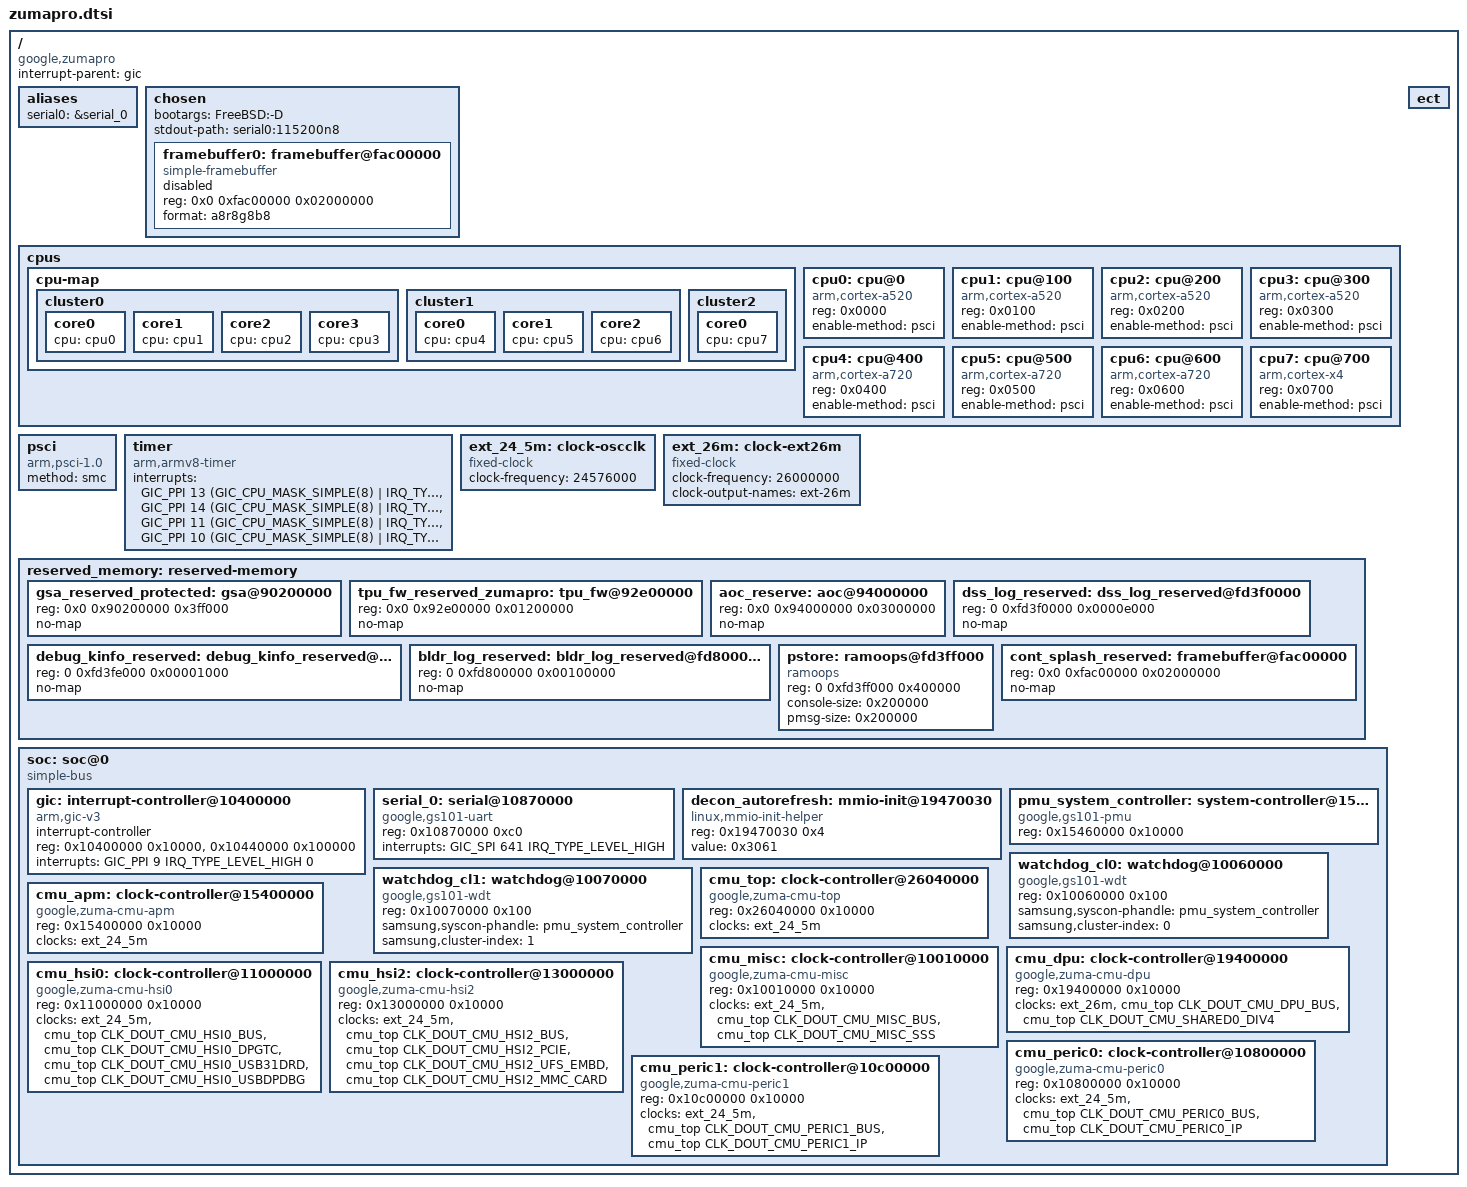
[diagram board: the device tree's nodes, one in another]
// SPDX-License-Identifier: (GPL-2.0-only OR BSD-2-Clause)
/*
 * Google Tensor G4 "zumapro" SoC.
 *
 * Minimal FreeBSD support: CPUs, PSCI, the GICv3 interrupt controller and
 * the ARM architected timer.  These are all handled by FreeBSD's generic
 * arm64 drivers.  SoC-specific clock (CMU), pinctrl and USI support is not
 * present yet; peripherals depend on the configuration left in place by the
 * bootloader.
 *
 * Copyright 2025 Trijal Saha <trijalsaha2012@gmail.com>
 */

#include <dt-bindings/clock/google,zuma.h>
#include <dt-bindings/interrupt-controller/arm-gic.h>

/ {
	compatible = "google,zumapro", "google,gs101";
	interrupt-parent = <&gic>;
	#address-cells = <2>;
	#size-cells = <1>;

	aliases {
		serial0 = &serial_0;
	};

	chosen {
		/*
		 * The stock bootloader crashes if /chosen has no "bootargs".
		 * FreeBSD only parses bootargs beginning with the "FreeBSD:"
		 * guard -- this is exactly how it ignores Linux-style args --
		 * and treats the remainder as boot flags.  "-D" sets
		 * RB_MULTIPLE so every probed console stays active; otherwise
		 * the vt_simplefb framebuffer (CN_INTERNAL) outranks and
		 * silences the serial console once cninit() picks one best
		 * console.
		 */
		bootargs = "FreeBSD:-D";
		stdout-path = "serial0:115200n8";
		
		/*
		 * Framebuffer set up by the bootloader.  FreeBSD's vt_simplefb
		 * driver takes the base address from "reg" (it does not follow
		 * the Linux "memory-region" phandle), so the splash buffer is
		 * described directly here and reserved below.  The per-board
		 * geometry (width, height, stride) is filled in and the node is
		 * enabled by each board's device tree.
		 */
		framebuffer0: framebuffer@fac00000 {
			compatible = "simple-framebuffer";
			reg = <0x0 0xfac00000 0x02000000>;
			format = "a8r8g8b8";
			status = "disabled";
		};
	};

	cpus {
		#address-cells = <1>;
		#size-cells = <0>;

		cpu-map {
			cluster0 {
				core0 { cpu = <&cpu0>; };
				core1 { cpu = <&cpu1>; };
				core2 { cpu = <&cpu2>; };
				core3 { cpu = <&cpu3>; };
			};

			cluster1 {
				core0 { cpu = <&cpu4>; };
				core1 { cpu = <&cpu5>; };
				core2 { cpu = <&cpu6>; };
			};

			cluster2 {
				core0 { cpu = <&cpu7>; };
			};
		};

		cpu0: cpu@0 {
			device_type = "cpu";
			compatible = "arm,cortex-a520";
			reg = <0x0000>;
			enable-method = "psci";
		};

		cpu1: cpu@100 {
			device_type = "cpu";
			compatible = "arm,cortex-a520";
			reg = <0x0100>;
			enable-method = "psci";
		};

		cpu2: cpu@200 {
			device_type = "cpu";
			compatible = "arm,cortex-a520";
			reg = <0x0200>;
			enable-method = "psci";
		};

		cpu3: cpu@300 {
			device_type = "cpu";
			compatible = "arm,cortex-a520";
			reg = <0x0300>;
			enable-method = "psci";
		};

		cpu4: cpu@400 {
			device_type = "cpu";
			compatible = "arm,cortex-a720";
			reg = <0x0400>;
			enable-method = "psci";
		};

		cpu5: cpu@500 {
			device_type = "cpu";
			compatible = "arm,cortex-a720";
			reg = <0x0500>;
			enable-method = "psci";
		};

		cpu6: cpu@600 {
			device_type = "cpu";
			compatible = "arm,cortex-a720";
			reg = <0x0600>;
			enable-method = "psci";
		};

		cpu7: cpu@700 {
			device_type = "cpu";
			compatible = "arm,cortex-x4";
			reg = <0x0700>;
			enable-method = "psci";
		};
	};

	psci {
		compatible = "arm,psci-1.0";
		method = "smc";
	};

	timer {
		compatible = "arm,armv8-timer";
		interrupts =
		    <GIC_PPI 13 (GIC_CPU_MASK_SIMPLE(8) | IRQ_TYPE_LEVEL_LOW) 0>,
		    <GIC_PPI 14 (GIC_CPU_MASK_SIMPLE(8) | IRQ_TYPE_LEVEL_LOW) 0>,
		    <GIC_PPI 11 (GIC_CPU_MASK_SIMPLE(8) | IRQ_TYPE_LEVEL_LOW) 0>,
		    <GIC_PPI 10 (GIC_CPU_MASK_SIMPLE(8) | IRQ_TYPE_LEVEL_LOW) 0>;
	};

	/*
	 * Reference oscillators.  The CMU clock controllers below take "oscclk"
	 * from ext_24_5m; its rate is the root of the whole clock tree.
	 */
	/*
	 * No clock-output-names: the FreeBSD fixed-clock driver would register
	 * it under that global name and collide with the "oscclk" node the
	 * exynos_clk driver registers internally.  The CMUs still reach this
	 * oscillator through their "oscclk" clock-names input (by phandle), so
	 * the rate is read from here while the global "oscclk" stays unique.
	 */
	ext_24_5m: clock-oscclk {
		compatible = "fixed-clock";
		#clock-cells = <0>;
		clock-frequency = <24576000>;
	};

	ext_26m: clock-ext26m {
		compatible = "fixed-clock";
		#clock-cells = <0>;
		clock-frequency = <26000000>;
		clock-output-names = "ext-26m";
	};

	/*
	 * Firmware and TrustZone carve-outs.  These must not be used by the
	 * kernel; they are reserved by the secure firmware and the bootloader.
	 */
	/* Energy/clock tables populated by the bootloader; must be present. */
	ect {
	};

	/*
	 * The stock bootloader inspects and populates these reserved regions
	 * before handing off, so the names, labels and addresses must match
	 * what it expects (i.e. the upstream Linux device tree) exactly.
	 */
	reserved_memory: reserved-memory {
		#address-cells = <2>;
		#size-cells = <1>;
		ranges;

		gsa_reserved_protected: gsa@90200000 {
			reg = <0x0 0x90200000 0x3ff000>;
			no-map;
		};

		tpu_fw_reserved_zumapro: tpu_fw@92e00000 {
			reg = <0x0 0x92e00000 0x01200000>;
			no-map;
		};

		aoc_reserve: aoc@94000000 {
			reg = <0x0 0x94000000 0x03000000>;
			no-map;
		};

		dss_log_reserved: dss_log_reserved@fd3f0000 {
			reg = <0 0xfd3f0000 0x0000e000>;
			no-map;
		};

		debug_kinfo_reserved: debug_kinfo_reserved@fd3fe000 {
			reg = <0 0xfd3fe000 0x00001000>;
			no-map;
		};

		bldr_log_reserved: bldr_log_reserved@fd800000 {
			reg = <0 0xfd800000 0x00100000>;
			no-map;
		};

		pstore: ramoops@fd3ff000 {
			compatible = "ramoops";
			reg = <0 0xfd3ff000 0x400000>;
			console-size = <0x200000>;
			pmsg-size = <0x200000>;
		};

		/*
		 * Bootloader splash / continuous-splash framebuffer.  Reserved
		 * so the kernel does not reuse it as RAM; consumed by the
		 * simple-framebuffer node under /chosen.  Sized to cover the
		 * largest panel of any board in this family.
		 */
		cont_splash_reserved: framebuffer@fac00000 {
			reg = <0x0 0xfac00000 0x02000000>;
			no-map;
		};
	};

	soc: soc@0 {
		compatible = "simple-bus";
		#address-cells = <1>;
		#size-cells = <1>;
		ranges = <0x0 0x0 0x0 0x40000000>;

		gic: interrupt-controller@10400000 {
			compatible = "arm,gic-v3";
			/*
			 * Four-cell binding to match the upstream Linux DTS.
			 * FreeBSD's gic_v3 driver uses the first three cells
			 * (type, number, flags) and ignores the fourth (the PPI
			 * partition index), which it does not implement.
			 */
			#interrupt-cells = <4>;
			interrupt-controller;
			reg = <0x10400000 0x10000>,	/* GICD */
			      <0x10440000 0x100000>;	/* GICR * 8 */
			interrupts = <GIC_PPI 9 IRQ_TYPE_LEVEL_HIGH 0>;
		};

		/*
		 * Debug UART (USI8 in UART mode).  The exynos4210-compatible
		 * UART is wrapped in a USI block; the USI mode and the gating
		 * clocks are left configured by the bootloader, so the UART is
		 * described directly here rather than under a USI node.
		 */
		serial_0: serial@10870000 {
			compatible = "google,gs101-uart";
			reg = <0x10870000 0xc0>;
			interrupts = <GIC_SPI 641 IRQ_TYPE_LEVEL_HIGH>;
		};

		/*
		 * Set the DECON display-controller autorefresh bit so the
		 * framebuffer the bootloader set up keeps scanning out.  This
		 * is a one-shot register write handled by the mmio_init driver.
		 */
		decon_autorefresh: mmio-init@19470030 {
			compatible = "linux,mmio-init-helper";
			reg = <0x19470030 0x4>;
			value = <0x3061>;
		};

		/*
		 * Power Management Unit register block, exposed as a syscon so
		 * the watchdog (and later reboot/poweroff) can reach the PMU
		 * reset controls.  FreeBSD's generic syscon driver binds on the
		 * "syscon" compatible; no PMU-specific driver, clock or USI is
		 * needed.
		 */
		pmu_system_controller: system-controller@15460000 {
			compatible = "google,gs101-pmu", "syscon";
			reg = <0x15460000 0x10000>;
		};

		/*
		 * CPU cluster watchdogs.  Placed after the PMU node so the
		 * syscon they reference attaches first (all bind in the same
		 * bus pass, in device-tree order).
		 */
		watchdog_cl0: watchdog@10060000 {
			compatible = "google,gs101-wdt";
			reg = <0x10060000 0x100>;
			samsung,syscon-phandle = <&pmu_system_controller>;
			samsung,cluster-index = <0>;
		};

		watchdog_cl1: watchdog@10070000 {
			compatible = "google,gs101-wdt";
			reg = <0x10070000 0x100>;
			samsung,syscon-phandle = <&pmu_system_controller>;
			samsung,cluster-index = <1>;
		};

		/*
		 * Clock Management Units.  CMU_TOP is the root of the clock
		 * tree; the other domains take their bus clocks from it.  The
		 * FreeBSD exynos_clk driver brings CMU_TOP up at an earlier bus
		 * pass so its outputs are registered before the leaf domains
		 * resolve them by name.  The samsung,sysreg phandles used by
		 * Linux for dynamic root-clock gating are omitted; that path is
		 * not implemented and the clocks are left as firmware set them.
		 */
		cmu_top: clock-controller@26040000 {
			compatible = "google,zuma-cmu-top";
			reg = <0x26040000 0x10000>;
			#clock-cells = <1>;
			clocks = <&ext_24_5m>;
			clock-names = "oscclk";
		};

		cmu_apm: clock-controller@15400000 {
			compatible = "google,zuma-cmu-apm";
			reg = <0x15400000 0x10000>;
			#clock-cells = <1>;
			clocks = <&ext_24_5m>;
			clock-names = "oscclk";
		};

		cmu_misc: clock-controller@10010000 {
			compatible = "google,zuma-cmu-misc";
			reg = <0x10010000 0x10000>;
			#clock-cells = <1>;
			clocks = <&ext_24_5m>,
				 <&cmu_top CLK_DOUT_CMU_MISC_BUS>,
				 <&cmu_top CLK_DOUT_CMU_MISC_SSS>;
			clock-names = "oscclk", "bus", "sss";
		};

		cmu_dpu: clock-controller@19400000 {
			compatible = "google,zuma-cmu-dpu";
			reg = <0x19400000 0x10000>;
			#clock-cells = <1>;
			clocks = <&ext_26m>,
				 <&cmu_top CLK_DOUT_CMU_DPU_BUS>,
				 <&cmu_top CLK_DOUT_CMU_SHARED0_DIV4>;
			clock-names = "oscclk", "bus", "dsim";
		};

		cmu_hsi0: clock-controller@11000000 {
			compatible = "google,zuma-cmu-hsi0";
			reg = <0x11000000 0x10000>;
			#clock-cells = <1>;
			clocks = <&ext_24_5m>,
				 <&cmu_top CLK_DOUT_CMU_HSI0_BUS>,
				 <&cmu_top CLK_DOUT_CMU_HSI0_DPGTC>,
				 <&cmu_top CLK_DOUT_CMU_HSI0_USB31DRD>,
				 <&cmu_top CLK_DOUT_CMU_HSI0_USBDPDBG>;
			clock-names = "oscclk", "bus", "dpgtc", "usb31drd",
				      "usbdpdbg";
		};

		cmu_hsi2: clock-controller@13000000 {
			compatible = "google,zuma-cmu-hsi2";
			reg = <0x13000000 0x10000>;
			#clock-cells = <1>;
			clocks = <&ext_24_5m>,
				 <&cmu_top CLK_DOUT_CMU_HSI2_BUS>,
				 <&cmu_top CLK_DOUT_CMU_HSI2_PCIE>,
				 <&cmu_top CLK_DOUT_CMU_HSI2_UFS_EMBD>,
				 <&cmu_top CLK_DOUT_CMU_HSI2_MMC_CARD>;
			clock-names = "oscclk", "bus", "pcie", "ufs", "mmc";
		};

		cmu_peric0: clock-controller@10800000 {
			compatible = "google,zuma-cmu-peric0";
			reg = <0x10800000 0x10000>;
			#clock-cells = <1>;
			clocks = <&ext_24_5m>,
				 <&cmu_top CLK_DOUT_CMU_PERIC0_BUS>,
				 <&cmu_top CLK_DOUT_CMU_PERIC0_IP>;
			clock-names = "oscclk", "bus", "ip";
		};

		cmu_peric1: clock-controller@10c00000 {
			compatible = "google,zuma-cmu-peric1";
			reg = <0x10c00000 0x10000>;
			#clock-cells = <1>;
			clocks = <&ext_24_5m>,
				 <&cmu_top CLK_DOUT_CMU_PERIC1_BUS>,
				 <&cmu_top CLK_DOUT_CMU_PERIC1_IP>;
			clock-names = "oscclk", "bus", "ip";
		};
	};
};
